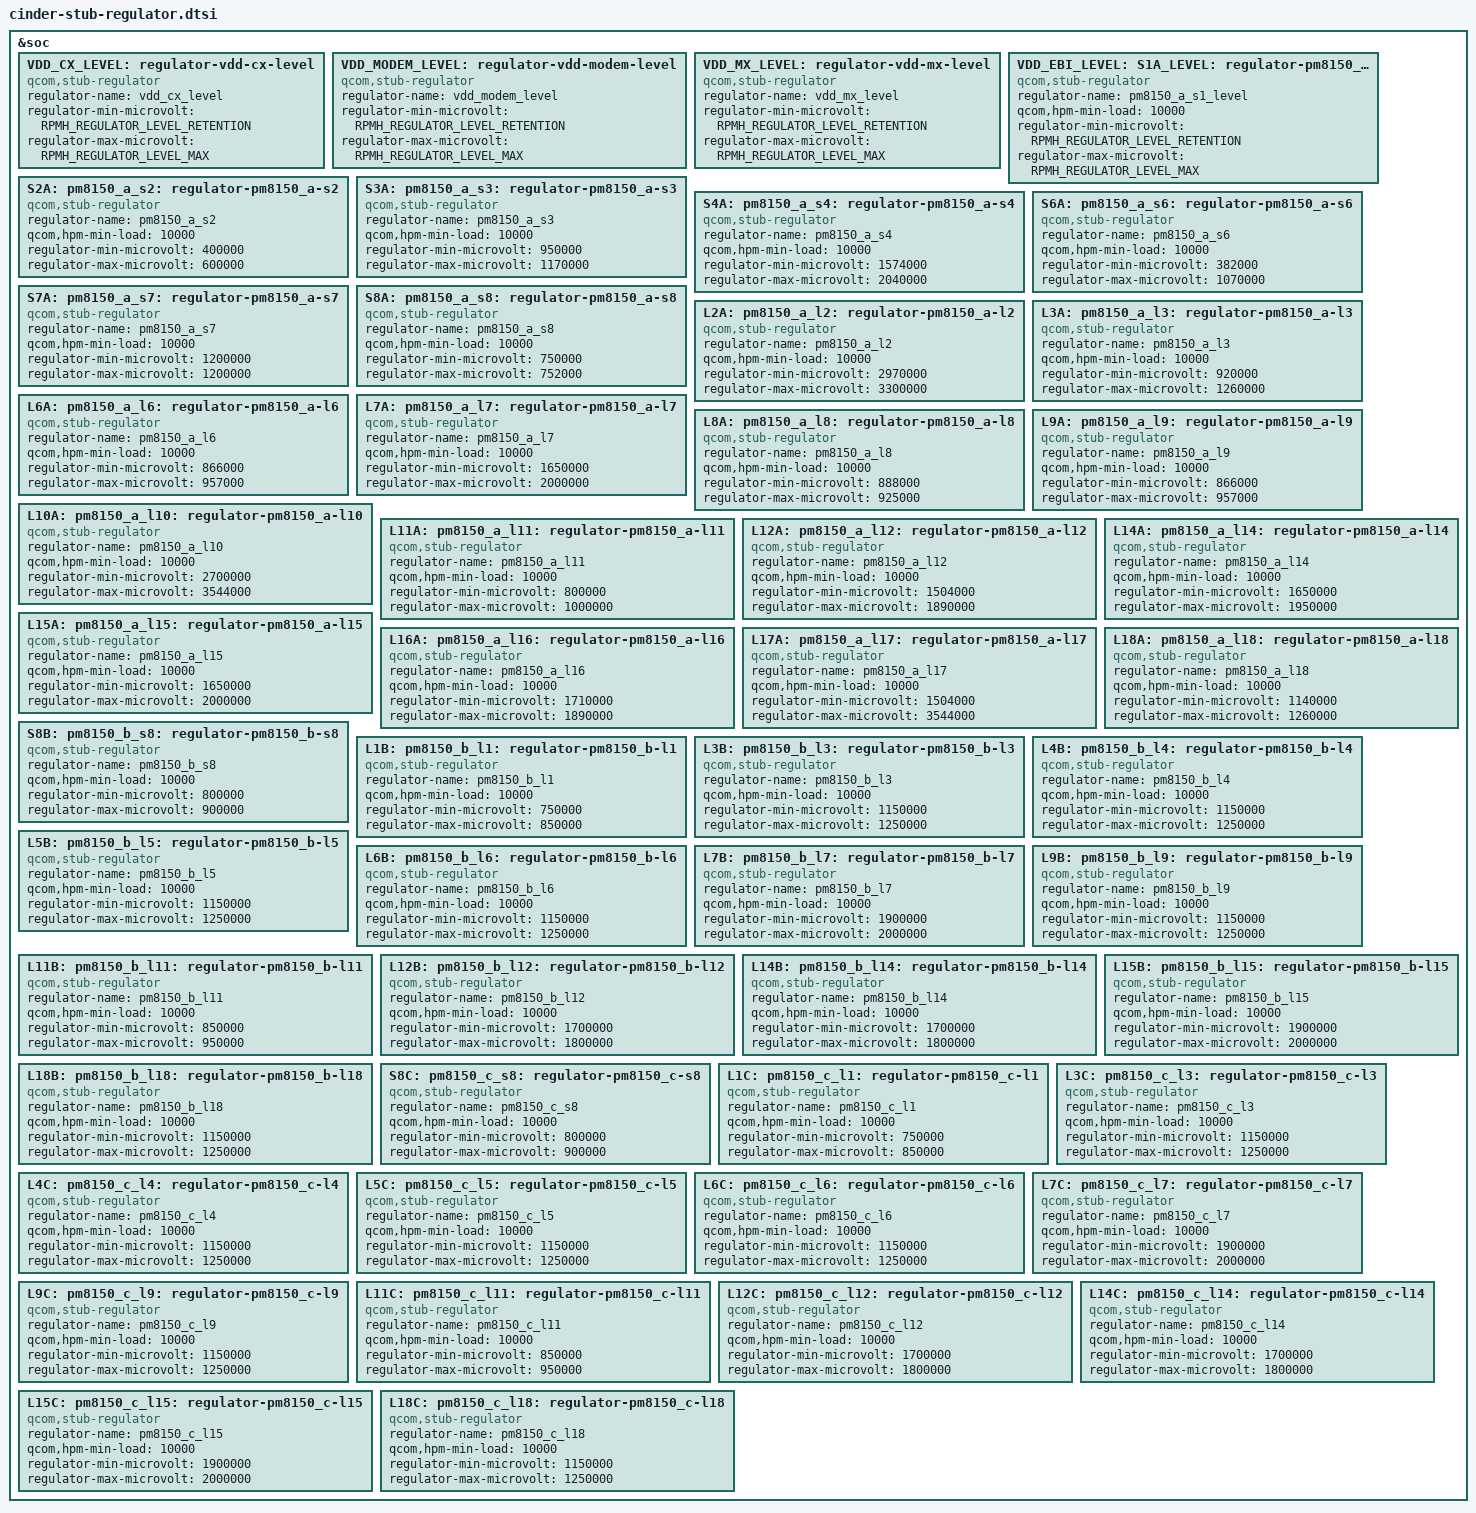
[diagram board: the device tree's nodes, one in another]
#include <dt-bindings/regulator/qcom,rpmh-regulator-levels.h>

&soc {
	VDD_CX_LEVEL: regulator-vdd-cx-level {
		compatible = "qcom,stub-regulator";
		regulator-name = "vdd_cx_level";
		regulator-min-microvolt = <RPMH_REGULATOR_LEVEL_RETENTION>;
		regulator-max-microvolt = <RPMH_REGULATOR_LEVEL_MAX>;
	};

	VDD_MODEM_LEVEL: regulator-vdd-modem-level {
		compatible = "qcom,stub-regulator";
		regulator-name = "vdd_modem_level";
		regulator-min-microvolt = <RPMH_REGULATOR_LEVEL_RETENTION>;
		regulator-max-microvolt = <RPMH_REGULATOR_LEVEL_MAX>;
	};

	VDD_MX_LEVEL: regulator-vdd-mx-level {
		compatible = "qcom,stub-regulator";
		regulator-name = "vdd_mx_level";
		regulator-min-microvolt = <RPMH_REGULATOR_LEVEL_RETENTION>;
		regulator-max-microvolt = <RPMH_REGULATOR_LEVEL_MAX>;
	};

	VDD_EBI_LEVEL:
	S1A_LEVEL:
	pm8150_a_s1_level: regulator-pm8150_a-s1-level {
		compatible = "qcom,stub-regulator";
		regulator-name = "pm8150_a_s1_level";
		qcom,hpm-min-load = <10000>;
		regulator-min-microvolt =
			<RPMH_REGULATOR_LEVEL_RETENTION>;
		regulator-max-microvolt = <RPMH_REGULATOR_LEVEL_MAX>;
	};

	S2A:
	pm8150_a_s2: regulator-pm8150_a-s2 {
		compatible = "qcom,stub-regulator";
		regulator-name = "pm8150_a_s2";
		qcom,hpm-min-load = <10000>;
		regulator-min-microvolt = <400000>;
		regulator-max-microvolt = <600000>;
	};

	S3A:
	pm8150_a_s3: regulator-pm8150_a-s3 {
		compatible = "qcom,stub-regulator";
		regulator-name = "pm8150_a_s3";
		qcom,hpm-min-load = <10000>;
		regulator-min-microvolt = <950000>;
		regulator-max-microvolt = <1170000>;
	};

	S4A:
	pm8150_a_s4: regulator-pm8150_a-s4 {
		compatible = "qcom,stub-regulator";
		regulator-name = "pm8150_a_s4";
		qcom,hpm-min-load = <10000>;
		regulator-min-microvolt = <1574000>;
		regulator-max-microvolt = <2040000>;
	};

	S6A:
	pm8150_a_s6: regulator-pm8150_a-s6 {
		compatible = "qcom,stub-regulator";
		regulator-name = "pm8150_a_s6";
		qcom,hpm-min-load = <10000>;
		regulator-min-microvolt = <382000>;
		regulator-max-microvolt = <1070000>;
	};

	S7A:
	pm8150_a_s7: regulator-pm8150_a-s7 {
		compatible = "qcom,stub-regulator";
		regulator-name = "pm8150_a_s7";
		qcom,hpm-min-load = <10000>;
		regulator-min-microvolt = <1200000>;
		regulator-max-microvolt = <1200000>;
	};

	S8A:
	pm8150_a_s8: regulator-pm8150_a-s8 {
		compatible = "qcom,stub-regulator";
		regulator-name = "pm8150_a_s8";
		qcom,hpm-min-load = <10000>;
		regulator-min-microvolt = <750000>;
		regulator-max-microvolt = <752000>;
	};

	L2A:
	pm8150_a_l2: regulator-pm8150_a-l2 {
		compatible = "qcom,stub-regulator";
		regulator-name = "pm8150_a_l2";
		qcom,hpm-min-load = <10000>;
		regulator-min-microvolt = <2970000>;
		regulator-max-microvolt = <3300000>;
	};

	L3A:
	pm8150_a_l3: regulator-pm8150_a-l3 {
		compatible = "qcom,stub-regulator";
		regulator-name = "pm8150_a_l3";
		qcom,hpm-min-load = <10000>;
		regulator-min-microvolt = <920000>;
		regulator-max-microvolt = <1260000>;
	};

	L6A:
	pm8150_a_l6: regulator-pm8150_a-l6 {
		compatible = "qcom,stub-regulator";
		regulator-name = "pm8150_a_l6";
		qcom,hpm-min-load = <10000>;
		regulator-min-microvolt = <866000>;
		regulator-max-microvolt = <957000>;
	};

	L7A:
	pm8150_a_l7: regulator-pm8150_a-l7 {
		compatible = "qcom,stub-regulator";
		regulator-name = "pm8150_a_l7";
		qcom,hpm-min-load = <10000>;
		regulator-min-microvolt = <1650000>;
		regulator-max-microvolt = <2000000>;
	};

	L8A:
	pm8150_a_l8: regulator-pm8150_a-l8 {
		compatible = "qcom,stub-regulator";
		regulator-name = "pm8150_a_l8";
		qcom,hpm-min-load = <10000>;
		regulator-min-microvolt = <888000>;
		regulator-max-microvolt = <925000>;
	};

	L9A:
	pm8150_a_l9: regulator-pm8150_a-l9 {
		compatible = "qcom,stub-regulator";
		regulator-name = "pm8150_a_l9";
		qcom,hpm-min-load = <10000>;
		regulator-min-microvolt = <866000>;
		regulator-max-microvolt = <957000>;
	};

	L10A:
	pm8150_a_l10: regulator-pm8150_a-l10 {
		compatible = "qcom,stub-regulator";
		regulator-name = "pm8150_a_l10";
		qcom,hpm-min-load = <10000>;
		regulator-min-microvolt = <2700000>;
		regulator-max-microvolt = <3544000>;
	};

	L11A:
	pm8150_a_l11: regulator-pm8150_a-l11 {
		compatible = "qcom,stub-regulator";
		regulator-name = "pm8150_a_l11";
		qcom,hpm-min-load = <10000>;
		regulator-min-microvolt = <800000>;
		regulator-max-microvolt = <1000000>;
	};

	L12A:
	pm8150_a_l12: regulator-pm8150_a-l12 {
		compatible = "qcom,stub-regulator";
		regulator-name = "pm8150_a_l12";
		qcom,hpm-min-load = <10000>;
		regulator-min-microvolt = <1504000>;
		regulator-max-microvolt = <1890000>;
	};

	L14A:
	pm8150_a_l14: regulator-pm8150_a-l14 {
		compatible = "qcom,stub-regulator";
		regulator-name = "pm8150_a_l14";
		qcom,hpm-min-load = <10000>;
		regulator-min-microvolt = <1650000>;
		regulator-max-microvolt = <1950000>;
	};

	L15A:
	pm8150_a_l15: regulator-pm8150_a-l15 {
		compatible = "qcom,stub-regulator";
		regulator-name = "pm8150_a_l15";
		qcom,hpm-min-load = <10000>;
		regulator-min-microvolt = <1650000>;
		regulator-max-microvolt = <2000000>;
	};

	L16A:
	pm8150_a_l16: regulator-pm8150_a-l16 {
		compatible = "qcom,stub-regulator";
		regulator-name = "pm8150_a_l16";
		qcom,hpm-min-load = <10000>;
		regulator-min-microvolt = <1710000>;
		regulator-max-microvolt = <1890000>;
	};

	L17A:
	pm8150_a_l17: regulator-pm8150_a-l17 {
		compatible = "qcom,stub-regulator";
		regulator-name = "pm8150_a_l17";
		qcom,hpm-min-load = <10000>;
		regulator-min-microvolt = <1504000>;
		regulator-max-microvolt = <3544000>;
	};

	L18A:
	pm8150_a_l18: regulator-pm8150_a-l18 {
		compatible = "qcom,stub-regulator";
		regulator-name = "pm8150_a_l18";
		qcom,hpm-min-load = <10000>;
		regulator-min-microvolt = <1140000>;
		regulator-max-microvolt = <1260000>;
	};

	S8B:
	pm8150_b_s8: regulator-pm8150_b-s8 {
		compatible = "qcom,stub-regulator";
		regulator-name = "pm8150_b_s8";
		qcom,hpm-min-load = <10000>;
		regulator-min-microvolt = <800000>;
		regulator-max-microvolt = <900000>;
	};

	L1B:
	pm8150_b_l1: regulator-pm8150_b-l1 {
		compatible = "qcom,stub-regulator";
		regulator-name = "pm8150_b_l1";
		qcom,hpm-min-load = <10000>;
		regulator-min-microvolt = <750000>;
		regulator-max-microvolt = <850000>;
	};

	L3B:
	pm8150_b_l3: regulator-pm8150_b-l3 {
		compatible = "qcom,stub-regulator";
		regulator-name = "pm8150_b_l3";
		qcom,hpm-min-load = <10000>;
		regulator-min-microvolt = <1150000>;
		regulator-max-microvolt = <1250000>;
	};

	L4B:
	pm8150_b_l4: regulator-pm8150_b-l4 {
		compatible = "qcom,stub-regulator";
		regulator-name = "pm8150_b_l4";
		qcom,hpm-min-load = <10000>;
		regulator-min-microvolt = <1150000>;
		regulator-max-microvolt = <1250000>;
	};

	L5B:
	pm8150_b_l5: regulator-pm8150_b-l5 {
		compatible = "qcom,stub-regulator";
		regulator-name = "pm8150_b_l5";
		qcom,hpm-min-load = <10000>;
		regulator-min-microvolt = <1150000>;
		regulator-max-microvolt = <1250000>;
	};

	L6B:
	pm8150_b_l6: regulator-pm8150_b-l6 {
		compatible = "qcom,stub-regulator";
		regulator-name = "pm8150_b_l6";
		qcom,hpm-min-load = <10000>;
		regulator-min-microvolt = <1150000>;
		regulator-max-microvolt = <1250000>;
	};

	L7B:
	pm8150_b_l7: regulator-pm8150_b-l7 {
		compatible = "qcom,stub-regulator";
		regulator-name = "pm8150_b_l7";
		qcom,hpm-min-load = <10000>;
		regulator-min-microvolt = <1900000>;
		regulator-max-microvolt = <2000000>;
	};

	L9B:
	pm8150_b_l9: regulator-pm8150_b-l9 {
		compatible = "qcom,stub-regulator";
		regulator-name = "pm8150_b_l9";
		qcom,hpm-min-load = <10000>;
		regulator-min-microvolt = <1150000>;
		regulator-max-microvolt = <1250000>;
	};

	L11B:
	pm8150_b_l11: regulator-pm8150_b-l11 {
		compatible = "qcom,stub-regulator";
		regulator-name = "pm8150_b_l11";
		qcom,hpm-min-load = <10000>;
		regulator-min-microvolt = <850000>;
		regulator-max-microvolt = <950000>;
	};

	L12B:
	pm8150_b_l12: regulator-pm8150_b-l12 {
		compatible = "qcom,stub-regulator";
		regulator-name = "pm8150_b_l12";
		qcom,hpm-min-load = <10000>;
		regulator-min-microvolt = <1700000>;
		regulator-max-microvolt = <1800000>;
	};

	L14B:
	pm8150_b_l14: regulator-pm8150_b-l14 {
		compatible = "qcom,stub-regulator";
		regulator-name = "pm8150_b_l14";
		qcom,hpm-min-load = <10000>;
		regulator-min-microvolt = <1700000>;
		regulator-max-microvolt = <1800000>;
	};

	L15B:
	pm8150_b_l15: regulator-pm8150_b-l15 {
		compatible = "qcom,stub-regulator";
		regulator-name = "pm8150_b_l15";
		qcom,hpm-min-load = <10000>;
		regulator-min-microvolt = <1900000>;
		regulator-max-microvolt = <2000000>;
	};

	L18B:
	pm8150_b_l18: regulator-pm8150_b-l18 {
		compatible = "qcom,stub-regulator";
		regulator-name = "pm8150_b_l18";
		qcom,hpm-min-load = <10000>;
		regulator-min-microvolt = <1150000>;
		regulator-max-microvolt = <1250000>;
	};

	S8C:
	pm8150_c_s8: regulator-pm8150_c-s8 {
		compatible = "qcom,stub-regulator";
		regulator-name = "pm8150_c_s8";
		qcom,hpm-min-load = <10000>;
		regulator-min-microvolt = <800000>;
		regulator-max-microvolt = <900000>;
	};

	L1C:
	pm8150_c_l1: regulator-pm8150_c-l1 {
		compatible = "qcom,stub-regulator";
		regulator-name = "pm8150_c_l1";
		qcom,hpm-min-load = <10000>;
		regulator-min-microvolt = <750000>;
		regulator-max-microvolt = <850000>;
	};

	L3C:
	pm8150_c_l3: regulator-pm8150_c-l3 {
		compatible = "qcom,stub-regulator";
		regulator-name = "pm8150_c_l3";
		qcom,hpm-min-load = <10000>;
		regulator-min-microvolt = <1150000>;
		regulator-max-microvolt = <1250000>;
	};

	L4C:
	pm8150_c_l4: regulator-pm8150_c-l4 {
		compatible = "qcom,stub-regulator";
		regulator-name = "pm8150_c_l4";
		qcom,hpm-min-load = <10000>;
		regulator-min-microvolt = <1150000>;
		regulator-max-microvolt = <1250000>;
	};

	L5C:
	pm8150_c_l5: regulator-pm8150_c-l5 {
		compatible = "qcom,stub-regulator";
		regulator-name = "pm8150_c_l5";
		qcom,hpm-min-load = <10000>;
		regulator-min-microvolt = <1150000>;
		regulator-max-microvolt = <1250000>;
	};

	L6C:
	pm8150_c_l6: regulator-pm8150_c-l6 {
		compatible = "qcom,stub-regulator";
		regulator-name = "pm8150_c_l6";
		qcom,hpm-min-load = <10000>;
		regulator-min-microvolt = <1150000>;
		regulator-max-microvolt = <1250000>;
	};

	L7C:
	pm8150_c_l7: regulator-pm8150_c-l7 {
		compatible = "qcom,stub-regulator";
		regulator-name = "pm8150_c_l7";
		qcom,hpm-min-load = <10000>;
		regulator-min-microvolt = <1900000>;
		regulator-max-microvolt = <2000000>;
	};

	L9C:
	pm8150_c_l9: regulator-pm8150_c-l9 {
		compatible = "qcom,stub-regulator";
		regulator-name = "pm8150_c_l9";
		qcom,hpm-min-load = <10000>;
		regulator-min-microvolt = <1150000>;
		regulator-max-microvolt = <1250000>;
	};

	L11C:
	pm8150_c_l11: regulator-pm8150_c-l11 {
		compatible = "qcom,stub-regulator";
		regulator-name = "pm8150_c_l11";
		qcom,hpm-min-load = <10000>;
		regulator-min-microvolt = <850000>;
		regulator-max-microvolt = <950000>;
	};

	L12C:
	pm8150_c_l12: regulator-pm8150_c-l12 {
		compatible = "qcom,stub-regulator";
		regulator-name = "pm8150_c_l12";
		qcom,hpm-min-load = <10000>;
		regulator-min-microvolt = <1700000>;
		regulator-max-microvolt = <1800000>;
	};

	L14C:
	pm8150_c_l14: regulator-pm8150_c-l14 {
		compatible = "qcom,stub-regulator";
		regulator-name = "pm8150_c_l14";
		qcom,hpm-min-load = <10000>;
		regulator-min-microvolt = <1700000>;
		regulator-max-microvolt = <1800000>;
	};

	L15C:
	pm8150_c_l15: regulator-pm8150_c-l15 {
		compatible = "qcom,stub-regulator";
		regulator-name = "pm8150_c_l15";
		qcom,hpm-min-load = <10000>;
		regulator-min-microvolt = <1900000>;
		regulator-max-microvolt = <2000000>;
	};

	L18C:
	pm8150_c_l18: regulator-pm8150_c-l18 {
		compatible = "qcom,stub-regulator";
		regulator-name = "pm8150_c_l18";
		qcom,hpm-min-load = <10000>;
		regulator-min-microvolt = <1150000>;
		regulator-max-microvolt = <1250000>;
	};
};
